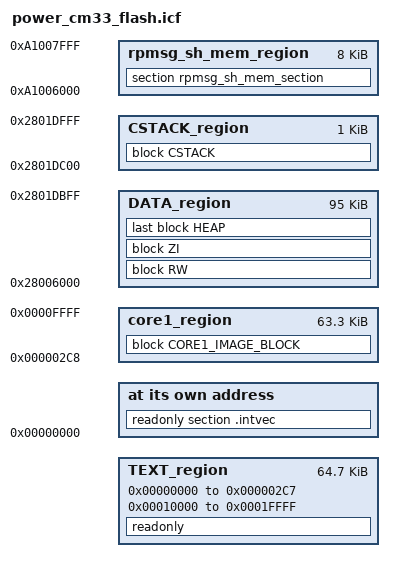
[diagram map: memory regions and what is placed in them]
/*
** ###################################################################
**     Processors:          MCXL255VDF_cm33
**                          MCXL255VLL_cm33
**
**     Compiler:            IAR ANSI C/C++ Compiler for ARM
**     Reference manual:    MCXL25xRM DraftF
**     Version:             rev. 1.0, 2023-01-09
**     Build:               b241211
**
**     Abstract:
**         Linker file for the IAR ANSI C/C++ Compiler for ARM
**
**     Copyright 2016 Freescale Semiconductor, Inc.
**     Copyright 2016-2024 NXP
**     SPDX-License-Identifier: BSD-3-Clause
**
**     http:                 www.nxp.com
**     mail:                 support@nxp.com
**
** ###################################################################
*/


/* Stack and Heap Sizes */
if (isdefinedsymbol(__stack_size__)) {
  define symbol __size_cstack__        = __stack_size__;
} else {
  define symbol __size_cstack__        = 0x0400;
}

if (isdefinedsymbol(__heap_size__)) {
  define symbol __size_heap__          = __heap_size__;
} else {
  define symbol __size_heap__          = 0x0400;
}

define symbol m_interrupts_start               = 0x00000000;
define symbol m_interrupts_end                 = 0x000002C7;

define symbol m_text_start                     = 0x00010000;
define symbol m_text_end                       = 0x0001FFFF;


define symbol m_data_start                     = 0x28006000;
define symbol m_data_end                       = 0x2801DFFF;

define symbol rpmsg_sh_mem_start               = 0xA1006000;
define symbol rpmsg_sh_mem_end                 = 0xA1007FFF;

define exported symbol core1_image_start     = 0x000002C8;
define exported symbol core1_image_end       = 0x0000FFFF;

define memory mem with size = 4G;

define region TEXT_region             = mem:[from m_interrupts_start to m_interrupts_end]
                                      | mem:[from m_text_start to m_text_end];
define region DATA_region = mem:[from m_data_start to m_data_end-__size_cstack__];

define region CSTACK_region = mem:[from m_data_end-__size_cstack__+1 to m_data_end];
if (isdefinedsymbol(__use_shmem__)) {
  define region rpmsg_sh_mem_region     = mem:[from rpmsg_sh_mem_start to rpmsg_sh_mem_end];
}

define region core1_region = mem:[from core1_image_start to core1_image_end];
define block CORE1_IMAGE_BLOCK          { section  __core1_image };

define block CSTACK    with alignment = 8, size = __size_cstack__   { };
define block HEAP      with alignment = 8, size = __size_heap__     { };
define block RW        { readwrite };
define block ZI        { zi };

initialize by copy { readwrite, section .textrw };

if (isdefinedsymbol(__USE_DLIB_PERTHREAD))
{
  /* Required in a multi-threaded application */
  initialize by copy with packing = none { section __DLIB_PERTHREAD };
}

if (isdefinedsymbol(__use_shmem__)) {
  do not initialize  { section rpmsg_sh_mem_section };
}

place at address mem: m_interrupts_start    { readonly section .intvec };
place in TEXT_region                        { readonly };
place in DATA_region                        { block RW };
place in DATA_region                        { block ZI };
place in DATA_region                        { last block HEAP };
place in CSTACK_region                      { block CSTACK };
if (isdefinedsymbol(__use_shmem__)) {
  place in rpmsg_sh_mem_region                { section rpmsg_sh_mem_section };
}
place in core1_region                       { block CORE1_IMAGE_BLOCK };
